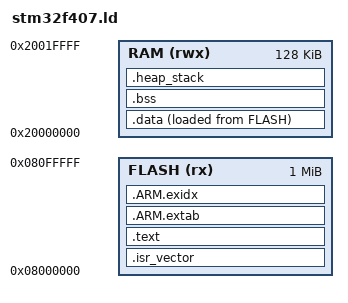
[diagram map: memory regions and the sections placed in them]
ENTRY(Reset_Handler)
MEMORY { FLASH (rx) : ORIGIN = 0x08000000, LENGTH = 1024K
         RAM (rwx) : ORIGIN = 0x20000000, LENGTH = 128K }
_estack = ORIGIN(RAM) + LENGTH(RAM);
SECTIONS {
 .isr_vector : { KEEP(*(.isr_vector)) } > FLASH
 .text : { *(.text*) *(.rodata*) KEEP(*(.init)) KEEP(*(.fini)) . = ALIGN(4); } > FLASH
 .ARM.extab : { *(.ARM.extab*) } > FLASH
 .ARM.exidx : { __exidx_start = .; *(.ARM.exidx*) __exidx_end = .; } > FLASH
 _sidata = LOADADDR(.data);
 .data : { . = ALIGN(4); _sdata = .; *(.data*) . = ALIGN(4); _edata = .; } > RAM AT> FLASH
 .bss (NOLOAD) : { . = ALIGN(4); _sbss = .; *(.bss*) *(COMMON) . = ALIGN(4); _ebss = .; } > RAM
 .heap_stack (NOLOAD) : { . = ALIGN(8); end = .; _end = .; __heap_start__ = .; . += 0x800; __heap_end__ = .; . += 0x2000; } > RAM
 /DISCARD/ : { *(.note*) *(.comment*) }
}
